# RK3399-AP register map
File version: 1
CPU: CA7 r0p1, little endian, MPU, FPU, I-cache, D-cache, VTOR, 4 interrupt priority bits, 0 interrupts
Registers are 32-bit, read-write, reset 0x0 unless marked. A register's access mark holds for its fields unless they carry their own. Offsets are from the block's base; [hi:lo] are bit positions.

## SPI0
Base 0xFF1C0000
Same registers: SPI1 0xFF1D0000, SPI2 0xFF1E0000, SPI4 0xFF1F0000, SPI5 0xFF200000, SPI3 0xFF350000
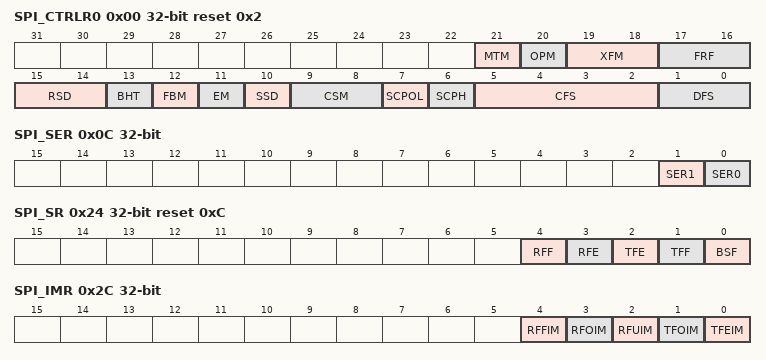
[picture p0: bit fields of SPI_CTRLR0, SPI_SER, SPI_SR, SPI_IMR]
0x00 SPI_CTRLR0 reset 0x2 — Control Register 0
  [21] MTM — Microwire Transfer Mode Valid when frame format is set to National Semiconductors Microwire. 1\'b0: non-sequential transfer 1\'b1: sequential transfer
  [20] OPM — Operation Mode 1\'b0: Master Mode 1\'b1: Slave Mode
  [19:18] XFM — Transfer Mode 2\'b00 :Transmit & Receive 2\'b01 : Transmit Only 2\'b10 : Receive Only 2\'b11 :reserved
  [17:16] FRF — Frame Format 2\'b00: Motorola SPI 2\'b01: Texas Instruments SSP 2\'b10: National Semiconductors Microwire 2\'b11 : Reserved
  [15:14] RSD — Rxd Sample Delay When SPI is configured as a master, if the rxd data cannot be sampled by the sclk_out edge at the right time, this register should be configured to define the number of the spi_clk cycles after the active sclk_out edge to sample rxd data later when SPI works at high frequency. 2\'b00:do not delay 2\'b01:1 cycle delay 2\'b10:2 cycles delay 2\'b11:3 cycles delay
  [13] BHT — Byte and Halfword Transform Valid when data frame size is 8bit. 1\'b0:apb 16bit write/read, spi 8bit write/read 1\'b1: apb 8bit write/read, spi 8bit write/read
  [12] FBM — First Bit Mode 1\'b0:first bit is MSB 1\'b1:first bit is LSB
  [11] EM — Endian Mode Serial endian mode can be configured by this bit. Apb endian mode is always little endian. 1\'b0:little endian 1\'b1:big endian
  [10] SSD — ss_n to sclk_out delay Valid when the frame format is set to Motorola SPI and SPI used as a master. 1\'b0: the period between ss_n active and sclk_out active is half sclk_out cycles. 1\'b1: the period between ss_n active and sclk_out active is one sclk_out cycle.
  [9:8] CSM — Chip Select Mode Valid when the frame format is set to Motorola SPI and SPI used as a master. 2\'b00: ss_n keep low after every frame data is transferred. 2\'b01:ss_n be high for half sclk_out cycles after every frame data is transferred. 2\'b10: ss_n be high for one sclk_out cycle after every frame data is transferred. 2\'b11:reserved
  [7] SCPOL — Serial Clock Polarity Valid when the frame format is set to Motorola SPI. 1\'b0: Inactive state of serial clock is low 1\'b1: Inactive state of serial clock is high
  [6] SCPH — Serial Clock Phase Valid when the frame format is set to Motorola SPI. 1\'b0: Serial clock toggles in middle of first data bit 1\'b1: Serial clock toggles at start of first data bit
  [5:2] CFS — Control Frame Size Selects the length of the control word for the Microwire frame format. 4\'b0000~0010:reserved 4\'b0011:4-bit serial data transfer 4\'b0100:5-bit serial data transfer 4\'b0101:6-bit serial data transfer 4\'b0110:7-bit serial data transfer 4\'b0111:8-bit serial data transfer 4\'b1000:9-bit serial data transfer 4\'b1001:10-bit serial data transfer 4\'b1010:11-bit serial data transfer 4\'b1011:12-bit serial data transfer 4\'b1100:13-bit serial data transfer 4\'b1101:14-bit serial data transfer 4\'b1110:15-bit serial data transfer 4\'b1111:16-bit serial data transfer
  [1:0] DFS — Data Frame Size Selects the data frame length. 2\'b00:4bit data 2\'b01:8bit data 2\'b10:16bit data 2\'b11:reserved
0x04 SPI_CTRLR1 — Control Register 1
  [15:0] NDM — Number of Data Frames When Transfer Mode is receive only, this register field sets the number of data frames to be continuously received by the SPI. The SPI continues to receive serial data until the number of data frames received is equal to this register value plus 1, which enables you to receive up to 64 KB of data in a continuous transfer.
0x08 SPI_ENR — SPI Enable
  [0] ENR — SPI Enable 1’b1: Enable all SPI operations. 1’b0: Disable all SPI operations Transmit and receive FIFO buffers are cleared when the device is disabled.
0x0C SPI_SER — Slave Enable Register
  [1] SER1 — Slave 1 Select Enable 1’b1: Enable chip select 1 1’b0: Disable chip select 1 This register is valid only when SPI is configured as a master device.
  [0] SER0 — Slave Select Enable 1’b1: Enable chip select 0 1’b0: Disable chip select 0 This register is valid only when SPI is configured as a master device.
0x10 SPI_BAUDR — Baud Rate Select
  [15:0] BAUDR — Baud Rate Select SPI Clock Divider. This register is valid only when the SPI is configured as a master device. The LSB for this field is always set to 0 and is unaffected by a write operation, which ensures an even value is held in this register. If the value is 0, the serial output clock (sclk_out) is disabled. The frequency of the sclk_out is derived from the following equation: Fsclk_out = Fspi_clk/ SCKDV Where SCKDV is any even value between 2 and 65534. For example: for Fspi_clk = 3.6864MHz and SCKDV =2 Fsclk_out = 3.6864/2= 1.8432MHz
0x14 SPI_TXFTLR — Transmit FIFO Threshold Level
  [4:0] TXFTLR — Transmit FIFO Threshold Level When the number of transmit FIFO entries is less than or equal to this value, the transmit FIFO empty interrupt is triggered.
0x18 SPI_RXFTLR — Receive FIFO Threshold Level
  [4:0] RXFTLR — Receive FIFO Threshold Level When the number of receive FIFO entries is greater than or equal to this value + 1, the receive FIFO full interrupt is triggered.
0x1C SPI_TXFLR ro — Transmit FIFO Level
  [5:0] TXFLR — Transmit FIFO Level Contains the number of valid data entries in the transmit FIFO.
0x20 SPI_RXFLR ro — Receive FIFO Level
  [5:0] RXFLR — Receive FIFO Level Contains the number of valid data entries in the receive FIFO.
0x24 SPI_SR ro reset 0xC — SPI Status
  [4] RFF — Receive FIFO Full 1\'b0: Receive FIFO is not full 1\'b1: Receive FIFO is full
  [3] RFE — Receive FIFO Empty 1\'b0: Receive FIFO is not empty 1\'b1: Receive FIFO is empty
  [2] TFE — Transmit FIFO Empty 1\'b0: Transmit FIFO is not empty 1\'b1: Transmit FIFO is empty
  [1] TFF — Transmit FIFO Full 1\'b0: Transmit FIFO is not full 1\'b1: Transmit FIFO is full
  [0] BSF — SPI Busy Flag When set, indicates that a serial transfer is in progress; when cleared indicates that the SPI is idle or disabled. 1\'b0: SPI is idle or disabled 1\'b1: SPI is actively transferring data
0x28 SPI_IPR — Interrupt Polarity
  [0] IPR — Interrupt Polarity Interrupt Polarity Register 1\'b0:Active Interrupt Polarity Level is HIGH 1\'b1: Active Interrupt Polarity Level is LOW
0x2C SPI_IMR — Interrupt Mask
  [4] RFFIM — Receive FIFO Full Interrupt Mask 1\'b0: spi_rxf_intr interrupt is masked 1\'b1: spi_rxf_intr interrupt is not masked
  [3] RFOIM — Receive FIFO Overflow Interrupt Mask 1\'b0: spi_rxo_intr interrupt is masked 1\'b1: spi_rxo_intr interrupt is not masked
  [2] RFUIM — Receive FIFO Underflow Interrupt Mask 1\'b0: spi_rxu_intr interrupt is masked 1\'b1: spi_rxu_intr interrupt is not masked
  [1] TFOIM — Transmit FIFO Overflow Interrupt Mask 1\'b0: spi_txo_intr interrupt is masked 1\'b1: spi_txo_intr interrupt is not masked
  [0] TFEIM — Transmit FIFO Empty Interrupt Mask 1\'b0: spi_txe_intr interrupt is masked 1\'b1: spi_txe_intr interrupt is not masked
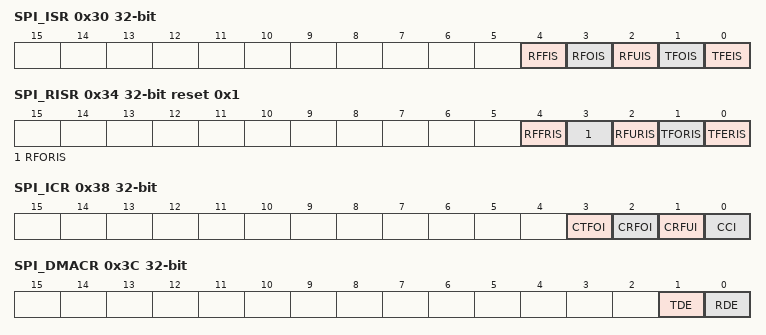
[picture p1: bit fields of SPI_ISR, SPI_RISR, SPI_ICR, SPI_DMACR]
0x30 SPI_ISR ro — Interrupt Status
  [4] RFFIS — Receive FIFO Full Interrupt Status 1\'b0: spi_rxf_intr interrupt is not active after masking 1\'b1: spi_rxf_intr interrupt is full after masking
  [3] RFOIS — Receive FIFO Overflow Interrupt Status 1\'b0: spi_rxo_intr interrupt is not active after masking 1\'b1: spi_rxo_intr interrupt is active after masking
  [2] RFUIS — Receive FIFO Underflow Interrupt Status 1\'b0: spi_rxu_intr interrupt is not active after masking 1\'b1: spi_rxu_intr interrupt is active after masking
  [1] TFOIS — Transmit FIFO Overflow Interrupt Status 1\'b0: spi_txo_intr interrupt is not active after masking 1\'b1: spi_txo_intr interrupt is active after masking
  [0] TFEIS — Transmit FIFO Empty Interrupt Status 1\'b0: spi_txe_intr interrupt is not active after masking 1\'b1: spi_txe_intr interrupt is active after masking
0x34 SPI_RISR ro reset 0x1 — Raw Interrupt Status
  [4] RFFRIS — Receive FIFO Full Raw Interrupt Status 1\'b0: spi_rxf_intr interrupt is not active prior to masking 1\'b1: spi_rxf_intr interrupt is full prior to masking
  [3] RFORIS — Receive FIFO Overflow Raw Interrupt Status 1\'b0 = spi_rxo_intr interrupt is not active prior to masking 1\'b1 = spi_rxo_intr interrupt is active prior to masking
  [2] RFURIS — Receive FIFO Underflow Raw Interrupt Status 1\'b0: spi_rxu_intr interrupt is not active prior to masking 1\'b1: spi_rxu_intr interrupt is active prior to masking
  [1] TFORIS — Transmit FIFO Overflow Raw Interrupt Status 1\'b0: spi_txo_intr interrupt is not active prior to masking 1\'b1: spi_txo_intr interrupt is active prior to masking
  [0] TFERIS — Transmit FIFO Empty Raw Interrupt Status 1\'b0: spi_txe_intr interrupt is not active prior to masking 1\'b1: spi_txe_intr interrupt is active prior to masking
0x38 SPI_ICR wo — Interrupt Clear
  [3] CTFOI — Clear Transmit FIFO Overflow Interrupt Write 1 to Clear Transmit FIFO Overflow Interrupt
  [2] CRFOI — Clear Receive FIFO Overflow Interrupt Write 1 to Clear Receive FIFO Overflow Interrupt
  [1] CRFUI — Clear Receive FIFO Underflow Interrupt Write 1 to Clear Receive FIFO Underflow Interrupt
  [0] CCI — Clear Combined Interrupt Write 1 to Clear Combined Interrupt
0x3C SPI_DMACR — DMA Control
  [1] TDE — Transmit DMA Enable 1\'b0: Transmit DMA disabled 1\'b1: Transmit DMA enabled
  [0] RDE — Receive DMA Enable 1\'b0: Receive DMA disabled 1\'b1: Receive DMA enabled
0x40 SPI_DMATDLR — DMA Transmit Data Level
  [4:0] TDL — Transmit Data Level This bit field controls the level at which a DMA request is made by the transmit logic. It is equal to the watermark level; that is, the dma_tx_req signal is generated when the number of valid data entries in the transmit FIFO is equal to or below this field value, and Transmit DMA Enable (DMACR[1]) = 1.
0x44 SPI_DMARDLR — DMA Receive Data Level
  [4:0] RDL — Receive Data Level This bit field controls the level at which a DMA request is made by the receive logic. The watermark level = DMARDL+1; that is, dma_rx_req is generated when the number of valid data entries in the receive FIFO is equal to or above this field value + 1, and Receive DMA Enable(DMACR[0])=1.
0x400 SPI_TXDR wo — Transmit FIFO Data
  [15:0] TXDR — Transimt FIFO Data Register. When it is written to, data are moved into the transmit FIFO.
0x800 SPI_RXDR — Receive FIFO Data
  [15:0] RXDR — Receive FIFO Data Register. When the register is read, data in the receive FIFO is accessed.
